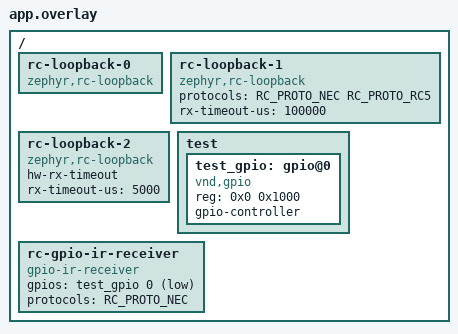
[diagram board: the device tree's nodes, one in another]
/*
 * SPDX-FileCopyrightText: Copyright (c) 2026 Linumiz
 * SPDX-License-Identifier: Apache-2.0
 */

#include <zephyr/dt-bindings/gpio/gpio.h>
#include <zephyr/dt-bindings/rc/rc-proto.h>

/ {
	rc-loopback-0 {
		compatible = "zephyr,rc-loopback";
		status = "okay";
	};

	rc-loopback-1 {
		compatible = "zephyr,rc-loopback";
		protocols = <RC_PROTO_NEC RC_PROTO_RC5>;
		rx-timeout-us = <100000>;
		status = "okay";
	};

	rc-loopback-2 {
		compatible = "zephyr,rc-loopback";
		hw-rx-timeout;
		rx-timeout-us = <5000>;
		status = "okay";
	};

	test {
		#address-cells = <1>;
		#size-cells = <1>;

		test_gpio: gpio@0 {
			compatible = "vnd,gpio";
			reg = <0x0 0x1000>;
			gpio-controller;
			#gpio-cells = <0x2>;
			status = "okay";
		};
	};

	rc-gpio-ir-receiver {
		compatible = "gpio-ir-receiver";
		gpios = <&test_gpio 0 GPIO_ACTIVE_LOW>;
		protocols = <RC_PROTO_NEC>;
		status = "okay";
	};
};
